VERSION "HIPBNYYYYYYYYYYYYYYYYYYYYYYYYYYYNNNNNNNNNN/4/%%%/4/'%**4NNN///"

NS_ :

BS_:

BU_: CPU_M CPU_H

BO_ 3221225472 VECTOR__INDEPENDENT_SIG_MSG: 0 Vector__XXX
 SG_ MotorT_SDOresp_Traction_Data : 0|64@1+ (1,0) [0|0] "" Vector__XXX
 SG_ Traction_SDOreq_MotorT_Data : 0|64@1+ (1,0) [0|0] "" Vector__XXX
 SG_ data : 0|8@1+ (1,0) [0|0] "" Vector__XXX
 SG_ Vehicle_dbg4_3 : 0|16@1- (1,0) [0|0] "" Vector__XXX
 SG_ Vehicle_dbg4_2 : 0|16@1- (1,0) [0|0] "" Vector__XXX
 SG_ Vehicle_dbg4_1 : 0|16@1- (1,0) [0|0] "" Vector__XXX
 SG_ Vehicle_dbg4_0 : 0|16@1- (1,0) [0|0] "" Vector__XXX
 SG_ Vehicle_dbg3_3 : 0|16@1- (1,0) [0|0] "" Vector__XXX
 SG_ Vehicle_dbg3_2 : 0|16@1- (1,0) [0|0] "" Vector__XXX
 SG_ Vehicle_dbg3_1 : 0|16@1- (1,0) [0|0] "" Vector__XXX
 SG_ Vehicle_dbg3_0 : 0|16@1- (1,0) [0|0] "" Vector__XXX
 SG_ Vehicle_dbg2_3 : 0|16@1- (1,0) [0|0] "" Vector__XXX
 SG_ Vehicle_dbg2_2 : 0|16@1- (1,0) [0|0] "" Vector__XXX
 SG_ Vehicle_dbg2_1 : 0|16@1- (1,0) [0|0] "" Vector__XXX
 SG_ Vehicle_dbg2_0 : 0|16@1- (1,0) [0|0] "" Vector__XXX
 SG_ Vehicle_dbg1_3 : 0|16@1- (1,0) [0|0] "" Vector__XXX
 SG_ Vehicle_dbg1_2 : 0|16@1- (1,0) [0|0] "" Vector__XXX
 SG_ Vehicle_dbg1_1 : 0|16@1- (1,0) [0|0] "" Vector__XXX
 SG_ Vehicle_dbg1_0 : 0|16@1- (1,0) [0|0] "" Vector__XXX
 SG_ Vehicle_dbg0_3 : 0|16@1- (1,0) [0|0] "" Vector__XXX
 SG_ Vehicle_dbg0_2 : 0|16@1- (1,0) [0|0] "" Vector__XXX
 SG_ Vehicle_dbg0_1 : 0|16@1- (1,0) [0|0] "" Vector__XXX
 SG_ Vehicle_dbg0_0 : 0|16@1- (1,0) [0|0] "" Vector__XXX
 SG_ VehicleMcuState : 0|8@1+ (1,0) [0|0] "" Vector__XXX
 SG_ TruckWorkTime : 0|32@1+ (1,0) [0|0] "sec" Vector__XXX
 SG_ MotorTrac_DTC4 : 0|16@1+ (1,0) [0|0] "" Vector__XXX
 SG_ MotorTrac_DTC3 : 0|16@1+ (1,0) [0|0] "" Vector__XXX
 SG_ MotorTrac_DTC2 : 0|16@1+ (1,0) [0|0] "" Vector__XXX
 SG_ MotorTrac_DTC1 : 0|16@1+ (1,0) [0|0] "" Vector__XXX
 SG_ T_pwmRatio_Lft : 0|16@1+ (0.1,0) [0|0] "%" Vector__XXX
 SG_ T_estBatCurr_Lft : 0|16@1- (1,0) [0|0] "A" Vector__XXX
 SG_ T_measSpeed_Lft : 0|16@1- (1,0) [0|0] "rpm" Vector__XXX
 SG_ T_estTorque_Lft : 0|16@1- (0.1,0) [0|0] "Nm" Vector__XXX
 SG_ T_DischargeActive_Lft : 0|1@1+ (1,0) [0|0] "" Vector__XXX
 SG_ T_AliveCount_Lft : 0|4@1+ (1,0) [0|0] "" Vector__XXX
 SG_ VT2_dm3 : 0|1@1- (1,0) [0|0] "" Vector__XXX
 SG_ VT2_dm2 : 0|1@1- (1,0) [0|0] "" Vector__XXX
 SG_ T_NoPwmSet_Lft : 0|1@1+ (1,0) [0|0] "" Vector__XXX
 SG_ VT2_dm4 : 0|1@1+ (1,0) [0|0] "" Vector__XXX
 SG_ T_NoSwEnable_Lft : 0|1@1+ (1,0) [0|0] "" Vector__XXX
 SG_ T_NoHwEnable_Lft : 0|1@1+ (1,0) [0|0] "" Vector__XXX
 SG_ T_MagnReady_Lft : 0|1@1+ (1,0) [0|0] "" Vector__XXX
 SG_ T_PWMstat_Lft : 0|1@1+ (1,0) [0|0] "" Vector__XXX
 SG_ T_ConvReady_Lft : 0|1@1+ (1,0) [0|0] "" Vector__XXX
 SG_ T_NoError_Lft : 0|2@1+ (1,0) [0|0] "" Vector__XXX
 SG_ T_statorFreq_Lft : 0|16@1- (1,0) [0|0] "Hz" Vector__XXX
 SG_ T_chipTemp_Lft : 0|8@1+ (1,-40) [0|0] "°C" Vector__XXX
 SG_ T_motTemp_Lft : 0|8@1+ (1,-40) [0|0] "°C" Vector__XXX
 SG_ T_statorCurrent_Lft : 0|16@1+ (1,0) [0|0] "A" Vector__XXX
 SG_ TF_dm7 : 0|8@1- (1,0) [0|0] "" Vector__XXX
 SG_ T_Discharge_Rgh_reserve : 0|1@1+ (1,0) [0|0] "" Vector__XXX
 SG_ TF_dm5 : 0|1@1- (1,0) [0|0] "" Vector__XXX
 SG_ TF_dm4 : 0|1@1- (1,0) [0|0] "" Vector__XXX
 SG_ TF_dm3 : 0|1@1- (1,0) [0|0] "" Vector__XXX
 SG_ TF_dm2 : 0|1@1- (1,0) [0|0] "" Vector__XXX
 SG_ T_Discharge_Lft : 0|1@1+ (1,0) [0|0] "" Vector__XXX
 SG_ TF_dm8 : 0|8@1+ (1,0) [0|0] "" Vector__XXX
 SG_ T_MessCountF : 0|4@1+ (1,0) [0|0] "" Vector__XXX
 SG_ T_PWMenableF_Rgh_reserve : 0|1@1+ (1,0) [0|0] "" Vector__XXX
 SG_ T_enableF_Rgh_reserve : 0|2@1+ (1,0) [0|0] "" Vector__XXX
 SG_ T_torqueSetF_Rgh_reserve : 0|16@1- (0.1,0) [0|0] "Nm" Vector__XXX
 SG_ T_PWMenableF_Lft : 0|1@1+ (1,0) [0|0] "" Vector__XXX
 SG_ T_enableF_Lft : 0|2@1+ (1,0) [0|0] "" Vector__XXX
 SG_ T_torqueSetF_Lft : 0|16@1- (0.1,0) [0|0] "Nm" Vector__XXX
 SG_ NodeID : 0|8@1+ (1,0) [0|0] "" Vector__XXX
 SG_ ServiceID : 0|8@1+ (1,0) [0|0] "" Vector__XXX

BO_ 1794 LiftHeartbt: 1 Vector__XXX
 SG_ LiftState : 0|8@1+ (1,0) [0|0] "" Vector__XXX

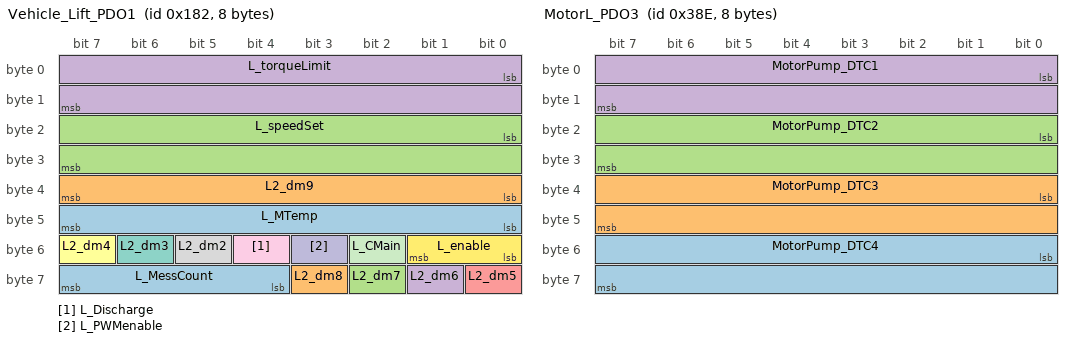
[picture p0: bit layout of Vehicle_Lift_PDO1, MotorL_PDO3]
BO_ 386 Vehicle_Lift_PDO1: 8 CPU_H
 SG_ L_MessCount : 60|4@1+ (1,0) [0|0] "" Vector__XXX
 SG_ L2_dm8 : 59|1@1- (1,0) [0|0] "" Vector__XXX
 SG_ L2_dm7 : 58|1@1- (1,0) [0|0] "" Vector__XXX
 SG_ L2_dm6 : 57|1@1- (1,0) [0|0] "" Vector__XXX
 SG_ L2_dm5 : 56|1@1- (1,0) [0|0] "" Vector__XXX
 SG_ L2_dm4 : 55|1@1- (1,0) [0|0] "" Vector__XXX
 SG_ L2_dm3 : 54|1@1- (1,0) [0|0] "" Vector__XXX
 SG_ L2_dm2 : 53|1@1- (1,0) [0|0] "" Vector__XXX
 SG_ L_Discharge : 52|1@1+ (1,0) [0|0] "" Vector__XXX
 SG_ L_PWMenable : 51|1@1+ (1,0) [0|0] "" Vector__XXX
 SG_ L_CMain : 50|1@1+ (1,0) [0|0] "" Vector__XXX
 SG_ L_enable : 48|2@1+ (1,0) [0|0] "" Vector__XXX
 SG_ L_MTemp : 40|8@1+ (1,-40) [-40|215] "°C" Vector__XXX
 SG_ L2_dm9 : 32|8@1- (1,0) [0|0] "" Vector__XXX
 SG_ L_speedSet : 16|16@1- (1,0) [0|0] "rpm"  CPU_M
 SG_ L_torqueLimit : 0|16@1- (0.1,0) [0|0] "Nm"  CPU_M

BO_ 1802 MotorHeartbt: 1 CPU_M
 SG_ MotorMcuState : 0|8@1+ (1,0) [0|0] "" Vector__XXX

BO_ 910 MotorL_PDO3: 8 CPU_M
 SG_ MotorPump_DTC4 : 48|16@1+ (1,0) [0|0] ""  CPU_H
 SG_ MotorPump_DTC3 : 32|16@1+ (1,0) [0|0] ""  CPU_H
 SG_ MotorPump_DTC2 : 16|16@1+ (1,0) [0|0] ""  CPU_H
 SG_ MotorPump_DTC1 : 0|16@1+ (1,0) [0|0] ""  CPU_H

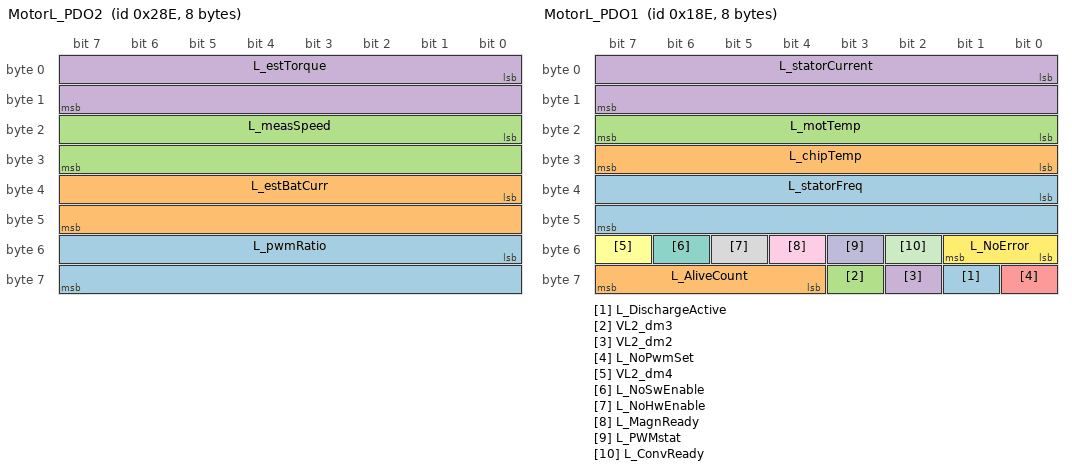
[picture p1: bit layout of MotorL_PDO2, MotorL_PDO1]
BO_ 654 MotorL_PDO2: 8 CPU_M
 SG_ L_pwmRatio : 48|16@1+ (0.1,0) [0|0] "%" Vector__XXX
 SG_ L_estBatCurr : 32|16@1- (1,0) [0|0] "A"  CPU_H
 SG_ L_measSpeed : 16|16@1- (1,0) [0|0] "rpm"  CPU_H
 SG_ L_estTorque : 0|16@1- (0.1,0) [0|0] "Nm"  CPU_H

BO_ 398 MotorL_PDO1: 8 CPU_M
 SG_ L_DischargeActive : 57|1@1+ (1,0) [0|0] "" Vector__XXX
 SG_ L_AliveCount : 60|4@1+ (1,0) [0|0] ""  CPU_H
 SG_ VL2_dm3 : 59|1@1- (1,0) [0|0] "" Vector__XXX
 SG_ VL2_dm2 : 58|1@1- (1,0) [0|0] "" Vector__XXX
 SG_ L_NoPwmSet : 56|1@1+ (1,0) [0|0] ""  CPU_H
 SG_ VL2_dm4 : 55|1@1+ (1,0) [0|0] "" Vector__XXX
 SG_ L_NoSwEnable : 54|1@1+ (1,0) [0|0] ""  CPU_H
 SG_ L_NoHwEnable : 53|1@1+ (1,0) [0|0] ""  CPU_H
 SG_ L_MagnReady : 52|1@1+ (1,0) [0|0] ""  CPU_H
 SG_ L_PWMstat : 51|1@1+ (1,0) [0|0] ""  CPU_H
 SG_ L_ConvReady : 50|1@1+ (1,0) [0|0] ""  CPU_H
 SG_ L_NoError : 48|2@1+ (1,0) [0|0] ""  CPU_H
 SG_ L_statorFreq : 32|16@1- (1,0) [0|0] "Hz"  CPU_H
 SG_ L_chipTemp : 24|8@1+ (1,-40) [0|0] "°C"  CPU_H
 SG_ L_motTemp : 16|8@1+ (1,-40) [0|0] "°C"  CPU_H
 SG_ L_statorCurrent : 0|16@1+ (1,0) [0|0] "A" Vector__XXX

BO_ 128 SYNC: 0 Vector__XXX

CM_ BU_ CPU_M "Twin-Powermodule, SAC-TP";
CM_ BO_ 3221225472 "This is a message for not used signals, created by Vector CANdb++ DBC OLE DB Provider.";
CM_ SG_ 3221225472 data "display-4£»Kcpc-0;Canbox wifi-1e;Kccu-22
";
CM_ SG_ 3221225472 T_ConvReady_Lft "2021/5/19update£ºset 1 when driver is enabled (needs HW signal INVx_ENABLE_CPUV and TLF_SS1) and all necessary CAN messages are received";
CM_ SG_ 3221225472 T_torqueSetF_Lft "torque demand";
CM_ SG_ 386 L_speedSet "speed demand";
CM_ SG_ 386 L_torqueLimit "torque limitation(CPU-M should not output bigger torque than this value)";
CM_ SG_ 398 L_ConvReady "It is set to false in case of a) no production test b) hw overvoltage c) KWP passive mode. 
2021/5/19update£ºset 1 when driver is enabled (needs HW signal INVx_ENABLE_CPUV and TLF_SS1) and all necessary CAN messages are received";
BA_DEF_ BU_  "NmStationAddress" INT 0 200;
BA_DEF_  "BusType" STRING ;
BA_DEF_  "Manufacturer" ENUM  "invalid","invalid","invalid","invalid","invalid","invalid","LINDE","invalid";
BA_DEF_  "NWM-Typ" ENUM  "invalid","invalid","invalid","invalid","invalid","invalid","invalid","invalid","invalid","invalid","LINDENM";
BA_DEF_ BO_  "GenMsgCycleTime" INT 0 180000;
BA_DEF_DEF_  "NmStationAddress" 0;
BA_DEF_DEF_  "BusType" "";
BA_DEF_DEF_  "Manufacturer" "LINDE";
BA_DEF_DEF_  "NWM-Typ" "LINDENM";
BA_DEF_DEF_  "GenMsgCycleTime" 0;
BA_ "BusType" "CAN";
BA_ "NmStationAddress" BU_ CPU_M 10;
BA_ "NmStationAddress" BU_ CPU_H 2;
BA_ "GenMsgCycleTime" BO_ 1794 40;
BA_ "GenMsgCycleTime" BO_ 386 10;
BA_ "GenMsgCycleTime" BO_ 1802 40;
BA_ "GenMsgCycleTime" BO_ 910 100;
BA_ "GenMsgCycleTime" BO_ 654 10;
BA_ "GenMsgCycleTime" BO_ 398 10;
BA_ "GenMsgCycleTime" BO_ 128 10;
VAL_ 3221225472 VehicleMcuState 127 "PREOPERATIONAL" 5 "OPERATIONAL" 4 "STOPPED" 0 "BOOTUP" ;
VAL_ 3221225472 NodeID 30 "wifi box" 6 "KCCU" 13 "LI-ION BMS" 4 "Display" 11 "VCtrl_Lift" 10 "VCtrl_Trac" 2 "Lift" 1 "Traction" 0 "AllNodes" ;
VAL_ 3221225472 ServiceID 130 "ResetCommunication" 129 "ResetNode" 128 "EnterPreOperational" 2 "StopRemoteNode" 1 "StartRemoteNode" ;
VAL_ 1802 MotorMcuState 127 "PREOPERATIONAL" 5 "OPERATIONAL" 4 "STOPPED" 0 "BOOTUP" ;
